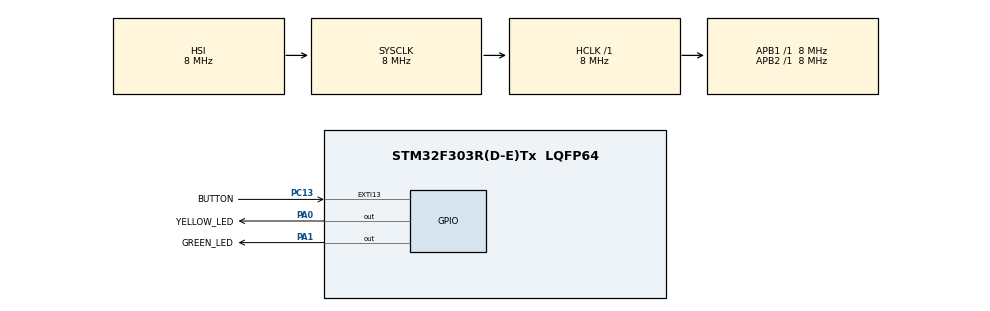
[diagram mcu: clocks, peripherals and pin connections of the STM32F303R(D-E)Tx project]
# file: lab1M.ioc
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Mcu.Family=STM32F3
Mcu.Name=STM32F303R(D-E)Tx
Mcu.Package=LQFP64
NVIC.EXTI15_10_IRQn=true\:0\:0\:false\:false\:true\:true\:true\:true
NVIC.PriorityGroup=NVIC_PRIORITYGROUP_4
PA0.GPIO_Label=YELLOW_LED
PA0.Signal=GPIO_Output
PA1.GPIO_Label=GREEN_LED
PA1.Signal=GPIO_Output
PC13.GPIO_Label=BUTTON
PC13.GPIO_ModeDefaultEXTI=GPIO_MODE_IT_FALLING
PC13.Signal=GPXTI13
ProjectManager.HeapSize=0x200
ProjectManager.StackSize=0x400
ProjectManager.TargetToolchain=STM32CubeIDE
RCC.AHBFreq_Value=8000000
RCC.APB1Freq_Value=8000000
RCC.APB2Freq_Value=8000000
RCC.CortexFreq_Value=8000000
RCC.HSE_VALUE=8000000
RCC.HSI_VALUE=8000000
RCC.LSE_VALUE=32768
RCC.SYSCLKFreq_VALUE=8000000
RCC.USBFreq_Value=16000000
board=custom

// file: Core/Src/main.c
/* USER CODE BEGIN Header */
/**
  ******************************************************************************
  * @file           : main.c
  * @brief          : Main program body
  ******************************************************************************
  * @attention
  *
  * Copyright (c) 2024 STMicroelectronics.
  * All rights reserved.
  *
  * This software is licensed under terms that can be found in the LICENSE file
  * in the root directory of this software component.
  * If no LICENSE file comes with this software, it is provided AS-IS.
  *
  ******************************************************************************
  */
/* USER CODE END Header */
#include "main.h"

/* USER CODE BEGIN PD */
#define YELLOW_ON_DELAY 5000     // 5 секунд
#define YELLOW_BLINK_DELAY 166   // 3 Гц блимання
#define BUTTON_COOLDOWN 10000    // 10 секунд (затримка перед перезапуском)
/* USER CODE END PD */

/* USER CODE BEGIN PV */
volatile uint8_t button_pressed = 0;
volatile uint32_t cycle_end_time = 0;
/* USER CODE END PV */

void SystemClock_Config(void);
static void MX_GPIO_Init(void);
/* USER CODE BEGIN PFP */
void TrafficLight_Process(void);
/* USER CODE END PFP */

/* USER CODE BEGIN 0 */
void HAL_GPIO_EXTI_Callback(uint16_t GPIO_Pin) {
    if (GPIO_Pin == BUTTON_Pin) {
        button_pressed = 1; // Кнопка натиснута
    }
}
/* USER CODE END 0 */

int main(void)
{

  /* MCU Configuration--------------------------------------------------------*/

  /* Reset of all peripherals, Initializes the Flash interface and the Systick. */
  HAL_Init();

  /* Configure the system clock */
  SystemClock_Config();

  /* Initialize all configured peripherals */
  MX_GPIO_Init();

  /* Infinite loop */
  /* USER CODE BEGIN WHILE */
  while (1)
  {
	TrafficLight_Process();
    /* USER CODE END WHILE */

  }
}

void SystemClock_Config(void)
{
  RCC_OscInitTypeDef RCC_OscInitStruct = {0};
  RCC_ClkInitTypeDef RCC_ClkInitStruct = {0};

  /** Initializes the RCC Oscillators according to the specified parameters
  * in the RCC_OscInitTypeDef structure.
  */
  RCC_OscInitStruct.OscillatorType = RCC_OSCILLATORTYPE_HSI;
  RCC_OscInitStruct.HSIState = RCC_HSI_ON;
  RCC_OscInitStruct.HSICalibrationValue = RCC_HSICALIBRATION_DEFAULT;
  RCC_OscInitStruct.PLL.PLLState = RCC_PLL_NONE;
  if (HAL_RCC_OscConfig(&RCC_OscInitStruct) != HAL_OK)
  {
    Error_Handler();
  }

  /** Initializes the CPU, AHB and APB buses clocks
  */
  RCC_ClkInitStruct.ClockType = RCC_CLOCKTYPE_HCLK|RCC_CLOCKTYPE_SYSCLK
                              |RCC_CLOCKTYPE_PCLK1|RCC_CLOCKTYPE_PCLK2;
  RCC_ClkInitStruct.SYSCLKSource = RCC_SYSCLKSOURCE_HSI;
  RCC_ClkInitStruct.AHBCLKDivider = RCC_SYSCLK_DIV1;
  RCC_ClkInitStruct.APB1CLKDivider = RCC_HCLK_DIV1;
  RCC_ClkInitStruct.APB2CLKDivider = RCC_HCLK_DIV1;

  if (HAL_RCC_ClockConfig(&RCC_ClkInitStruct, FLASH_LATENCY_0) != HAL_OK)
  {
    Error_Handler();
  }
}

static void MX_GPIO_Init(void)
{
  GPIO_InitTypeDef GPIO_InitStruct = {0};

  /* GPIO Ports Clock Enable */
  __HAL_RCC_GPIOC_CLK_ENABLE();
  __HAL_RCC_GPIOA_CLK_ENABLE();

  /*Configure GPIO pin Output Level */
  HAL_GPIO_WritePin(GPIOA, YELLOW_LED_Pin|GREEN_LED_Pin, GPIO_PIN_RESET);

  /*Configure GPIO pin : BUTTON_Pin */
  GPIO_InitStruct.Pin = BUTTON_Pin;
  GPIO_InitStruct.Mode = GPIO_MODE_IT_FALLING;
  GPIO_InitStruct.Pull = GPIO_NOPULL;
  HAL_GPIO_Init(BUTTON_GPIO_Port, &GPIO_InitStruct);

  /*Configure GPIO pins : YELLOW_LED_Pin GREEN_LED_Pin */
  GPIO_InitStruct.Pin = YELLOW_LED_Pin|GREEN_LED_Pin;
  GPIO_InitStruct.Mode = GPIO_MODE_OUTPUT_PP;
  GPIO_InitStruct.Pull = GPIO_NOPULL;
  GPIO_InitStruct.Speed = GPIO_SPEED_FREQ_LOW;
  HAL_GPIO_Init(GPIOA, &GPIO_InitStruct);

  /* EXTI interrupt init*/
  HAL_NVIC_SetPriority(EXTI15_10_IRQn, 0, 0);
  HAL_NVIC_EnableIRQ(EXTI15_10_IRQn);

}

/* USER CODE BEGIN 4 */
void TrafficLight_Process(void) {
    // Жовтий світлодіод горить 5 секунд
    HAL_GPIO_WritePin(YELLOW_LED_GPIO_Port, YELLOW_LED_Pin, GPIO_PIN_SET);
    HAL_Delay(YELLOW_ON_DELAY);
    HAL_GPIO_WritePin(YELLOW_LED_GPIO_Port, YELLOW_LED_Pin, GPIO_PIN_RESET);

    // Жовтий світлодіод блимає 2 секунди (3 Гц)
    for (int i = 0; i < 12; i++) {
        HAL_GPIO_TogglePin(YELLOW_LED_GPIO_Port, YELLOW_LED_Pin);
        HAL_Delay(YELLOW_BLINK_DELAY);
    }
    HAL_GPIO_WritePin(YELLOW_LED_GPIO_Port, YELLOW_LED_Pin, GPIO_PIN_RESET);

    // Зелений світлодіод горить до натискання кнопки
    HAL_GPIO_WritePin(GREEN_LED_GPIO_Port, GREEN_LED_Pin, GPIO_PIN_SET);
    button_pressed = 0;
    // Фіксуємо час завершення циклу
    cycle_end_time = HAL_GetTick();
    while (!button_pressed) {
        HAL_Delay(100);
    }
    HAL_GPIO_WritePin(GREEN_LED_GPIO_Port, GREEN_LED_Pin, GPIO_PIN_RESET);
    // Очікуємо мінімум 10 секунд після завершення циклу
    while ((HAL_GetTick() - cycle_end_time) < BUTTON_COOLDOWN) {
        HAL_Delay(100); // Затримка для зменшення навантаження на CPU
    }

    button_pressed = 0; // Скидаємо стан кнопки
}
/* USER CODE END 4 */

void Error_Handler(void)
{
  __disable_irq();
  while (1)
  {
  }
}
